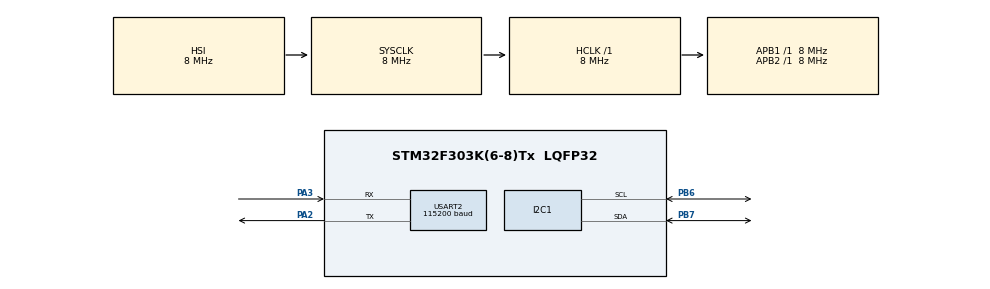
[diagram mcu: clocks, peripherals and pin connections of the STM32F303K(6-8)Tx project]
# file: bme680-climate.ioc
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I2C1.Timing=0x00201D2B
Mcu.Family=STM32F3
Mcu.Name=STM32F303K(6-8)Tx
Mcu.Package=LQFP32
NVIC.I2C1_EV_IRQn=true\:0\:0\:false\:false\:true\:true\:true\:true
NVIC.PriorityGroup=NVIC_PRIORITYGROUP_4
NVIC.USART2_IRQn=true\:0\:0\:false\:false\:true\:true\:true\:true
PA2.Mode=Asynchronous
PA2.Signal=USART2_TX
PA3.Mode=Asynchronous
PA3.Signal=USART2_RX
PB6.Mode=I2C
PB6.Signal=I2C1_SCL
PB7.Mode=I2C
PB7.Signal=I2C1_SDA
ProjectManager.HeapSize=0x200
ProjectManager.StackSize=0x400
ProjectManager.TargetToolchain=STM32CubeIDE
RCC.AHBFreq_Value=8000000
RCC.APB1Freq_Value=8000000
RCC.APB2Freq_Value=8000000
RCC.CortexFreq_Value=8000000
RCC.HSE_VALUE=8000000
RCC.HSI_VALUE=8000000
RCC.SYSCLKFreq_VALUE=8000000
USART2.BaudRate=115200
USART2.VirtualMode-Asynchronous=VM_ASYNC
board=custom

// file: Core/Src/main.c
/* USER CODE BEGIN Header */
/**
  ******************************************************************************
  * @file           : main.c
  * @brief          : Main program body
  ******************************************************************************
  * @attention
  *
  * Copyright (c) 2024 STMicroelectronics.
  * All rights reserved.
  *
  * This software is licensed under terms that can be found in the LICENSE file
  * in the root directory of this software component.
  * If no LICENSE file comes with this software, it is provided AS-IS.
  *
  ******************************************************************************
  */
/* USER CODE END Header */
#include "main.h"
#include "i2c.h"
#include "usart.h"
#include "gpio.h"
#include "bme680.h"
#include <stdio.h>
#include <string.h>

float temperature, pressure, humidity;

void SystemClock_Config(void);

int main(void)
{

  /* MCU Configuration--------------------------------------------------------*/

  /* Reset of all peripherals, Initializes the Flash interface and the Systick. */
  HAL_Init();

  /* Configure the system clock */
  SystemClock_Config();

  /* Initialize all configured peripherals */
  MX_GPIO_Init();
  MX_I2C1_Init();
  MX_USART2_UART_Init();
  /* USER CODE BEGIN 2 */
  HAL_UART_Transmit(&huart2, (uint8_t *)"Starting BME680 Initialization\n", 31, HAL_MAX_DELAY);
  if (BME680_Init() == HAL_OK) {
      HAL_UART_Transmit(&huart2, (uint8_t *)"BME680 Initialized Successfully\n", 33, HAL_MAX_DELAY);
  } else {
      HAL_UART_Transmit(&huart2, (uint8_t *)"BME680 Initialization Failed\n", 29, HAL_MAX_DELAY);
      Error_Handler();  // LED will start blinking here
  }
  /* USER CODE END 2 */

  /* Infinite loop */
  /* USER CODE BEGIN WHILE */
  while (1) {
          // Read Temperature from BME680 Sensor
          if (BME680_ReadTemperature(&temperature) == HAL_OK) {
              // Sanity check for temperature range (assuming the sensor works between -40 to +85 degrees Celsius)
              if (temperature > -40.0f && temperature < 85.0f) {
            	  int temp_int = (int)temperature;  // Integer part
            	  int temp_frac = (int)((temperature - temp_int) * 100);  // Fractional part (2 decimal places)

            	  char msg[50];
            	  sprintf(msg, "Temperature: %d.%02d C\r\n", temp_int, temp_frac);
            	  HAL_UART_Transmit(&huart2, (uint8_t *)msg, strlen(msg), HAL_MAX_DELAY);
              } else {
                  HAL_UART_Transmit(&huart2, (uint8_t *)"Invalid temperature value\r\n", 26, HAL_MAX_DELAY);
              }
          } else {
              HAL_UART_Transmit(&huart2, (uint8_t *)"Failed to read temperature\r\n", 27, HAL_MAX_DELAY);
          }

          HAL_Delay(1000); // 1-second delay between readings
      }
  /* USER CODE END 3 */
}

void SystemClock_Config(void)
{
  RCC_OscInitTypeDef RCC_OscInitStruct = {0};
  RCC_ClkInitTypeDef RCC_ClkInitStruct = {0};
  RCC_PeriphCLKInitTypeDef PeriphClkInit = {0};

  /** Initializes the RCC Oscillators according to the specified parameters
  * in the RCC_OscInitTypeDef structure.
  */
  RCC_OscInitStruct.OscillatorType = RCC_OSCILLATORTYPE_HSI;
  RCC_OscInitStruct.HSIState = RCC_HSI_ON;
  RCC_OscInitStruct.HSICalibrationValue = RCC_HSICALIBRATION_DEFAULT;
  RCC_OscInitStruct.PLL.PLLState = RCC_PLL_NONE;
  if (HAL_RCC_OscConfig(&RCC_OscInitStruct) != HAL_OK)
  {
    Error_Handler();
  }

  /** Initializes the CPU, AHB and APB buses clocks
  */
  RCC_ClkInitStruct.ClockType = RCC_CLOCKTYPE_HCLK|RCC_CLOCKTYPE_SYSCLK
                              |RCC_CLOCKTYPE_PCLK1|RCC_CLOCKTYPE_PCLK2;
  RCC_ClkInitStruct.SYSCLKSource = RCC_SYSCLKSOURCE_HSI;
  RCC_ClkInitStruct.AHBCLKDivider = RCC_SYSCLK_DIV1;
  RCC_ClkInitStruct.APB1CLKDivider = RCC_HCLK_DIV1;
  RCC_ClkInitStruct.APB2CLKDivider = RCC_HCLK_DIV1;

  if (HAL_RCC_ClockConfig(&RCC_ClkInitStruct, FLASH_LATENCY_0) != HAL_OK)
  {
    Error_Handler();
  }
  PeriphClkInit.PeriphClockSelection = RCC_PERIPHCLK_I2C1;
  PeriphClkInit.I2c1ClockSelection = RCC_I2C1CLKSOURCE_HSI;
  if (HAL_RCCEx_PeriphCLKConfig(&PeriphClkInit) != HAL_OK)
  {
    Error_Handler();
  }
}

void Error_Handler(void) {
    // Stay here if an error occurs
	HAL_GPIO_WritePin(GPIOA, GPIO_PIN_5, GPIO_PIN_SET);
	    // Stay here if an error occurs
	    while (1) {
	        // Toggle the LED to indicate an error
	        HAL_GPIO_TogglePin(GPIOA, GPIO_PIN_5);
	        HAL_Delay(500); // 500 ms delay for blinking
	    }
}
